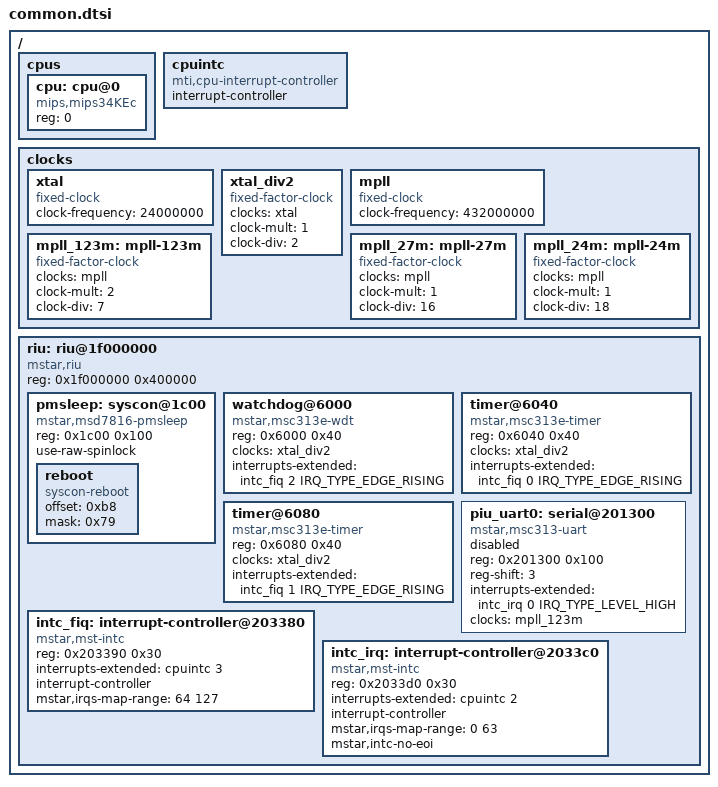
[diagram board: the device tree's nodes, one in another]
// SPDX-License-Identifier: GPL-2.0

#include <dt-bindings/interrupt-controller/irq.h>

/ {
	#address-cells = <1>;
	#size-cells = <1>;

	cpus {
		#address-cells = <1>;
		#size-cells = <0>;

		cpu: cpu@0 {
			device_type = "cpu";
			compatible = "mips,mips34KEc";
			reg = <0>;
		};
	};

	cpuintc: cpuintc {
		compatible = "mti,cpu-interrupt-controller";
		#interrupt-cells = <1>;
		interrupt-controller;
	};

	clocks: clocks {
		xtal: xtal {
			compatible = "fixed-clock";
			#clock-cells = <0>;
			clock-frequency = <24000000>;
		};

		xtal_div2: xtal_div2 {
			compatible = "fixed-factor-clock";
			#clock-cells = <0>;
			clocks = <&xtal>;
			clock-mult = <1>;
			clock-div = <2>;
		};

		/* TODO */
		mpll: mpll {
			compatible = "fixed-clock";
			#clock-cells = <0>;
			clock-frequency = <432000000>;
		};

		mpll_123m: mpll-123m { // 123.4285 MHz
			compatible = "fixed-factor-clock";
			#clock-cells = <0>;
			clocks = <&mpll>;
			clock-mult = <2>;
			clock-div = <7>;
		};

		mpll_27m: mpll-27m {
			compatible = "fixed-factor-clock";
			#clock-cells = <0>;
			clocks = <&mpll>;
			clock-mult = <1>;
			clock-div = <16>;
		};

		mpll_24m: mpll-24m {
			compatible = "fixed-factor-clock";
			#clock-cells = <0>;
			clocks = <&mpll>;
			clock-mult = <1>;
			clock-div = <18>;
		};
	};

	riu: riu@1f000000 {
		#address-cells = <1>;
		#size-cells = <1>;
		compatible = "mstar,riu", "simple-bus";
		reg = <0x1f000000 0x400000>;
		ranges = <0x0 0x1f000000 0x400000>;

		/*----------------------- PM RIU area -----------------------*/

		pmsleep: syscon@1c00 {
			compatible = "mstar,msd7816-pmsleep",
							"syscon", "simple-mfd";
			reg = <0x1c00 0x100>;
			use-raw-spinlock;

			reboot {
				compatible = "syscon-reboot";
				offset = <0xb8>;
				mask = <0x79>;
			};
		};

		watchdog@6000 {
			compatible = "mstar,msc313e-wdt";
			reg = <0x6000 0x40>;
			clocks = <&xtal_div2>;
			interrupts-extended = <&intc_fiq 2 IRQ_TYPE_EDGE_RISING>;
		};

		timer@6040 {
			compatible = "mstar,msc313e-timer";
			reg = <0x6040 0x40>;
			clocks = <&xtal_div2>;
			interrupts-extended = <&intc_fiq 0 IRQ_TYPE_EDGE_RISING>;
		};

		timer@6080 {
			compatible = "mstar,msc313e-timer";
			reg = <0x6080 0x40>;
			clocks = <&xtal_div2>;
			interrupts-extended = <&intc_fiq 1 IRQ_TYPE_EDGE_RISING>;
		};

		/*-------------------- Non-PM RIU area ----------------------*/

		piu_uart0: serial@201300 {
			compatible = "mstar,msc313-uart", "snps,dw-apb-uart";
			reg = <0x201300 0x100>;
			reg-shift = <3>;
			interrupts-extended = <&intc_irq 0 IRQ_TYPE_LEVEL_HIGH>;
			clocks = <&mpll_123m>; // TODO, clkgen!
			status = "disabled";
		};

		intc_fiq: interrupt-controller@203380 {
			compatible = "mstar,mst-intc";
			reg = <0x203390 0x30>;
			interrupts-extended = <&cpuintc 3>;
			interrupt-controller;
			#interrupt-cells = <2>;
			mstar,irqs-map-range = <64 127>;
		};

		intc_irq: interrupt-controller@2033c0 {
			compatible = "mstar,mst-intc";
			reg = <0x2033d0 0x30>;
			interrupts-extended = <&cpuintc 2>;
			interrupt-controller;
			#interrupt-cells = <2>;
			mstar,irqs-map-range = <0 63>;
			mstar,intc-no-eoi;
		};
	};
};
